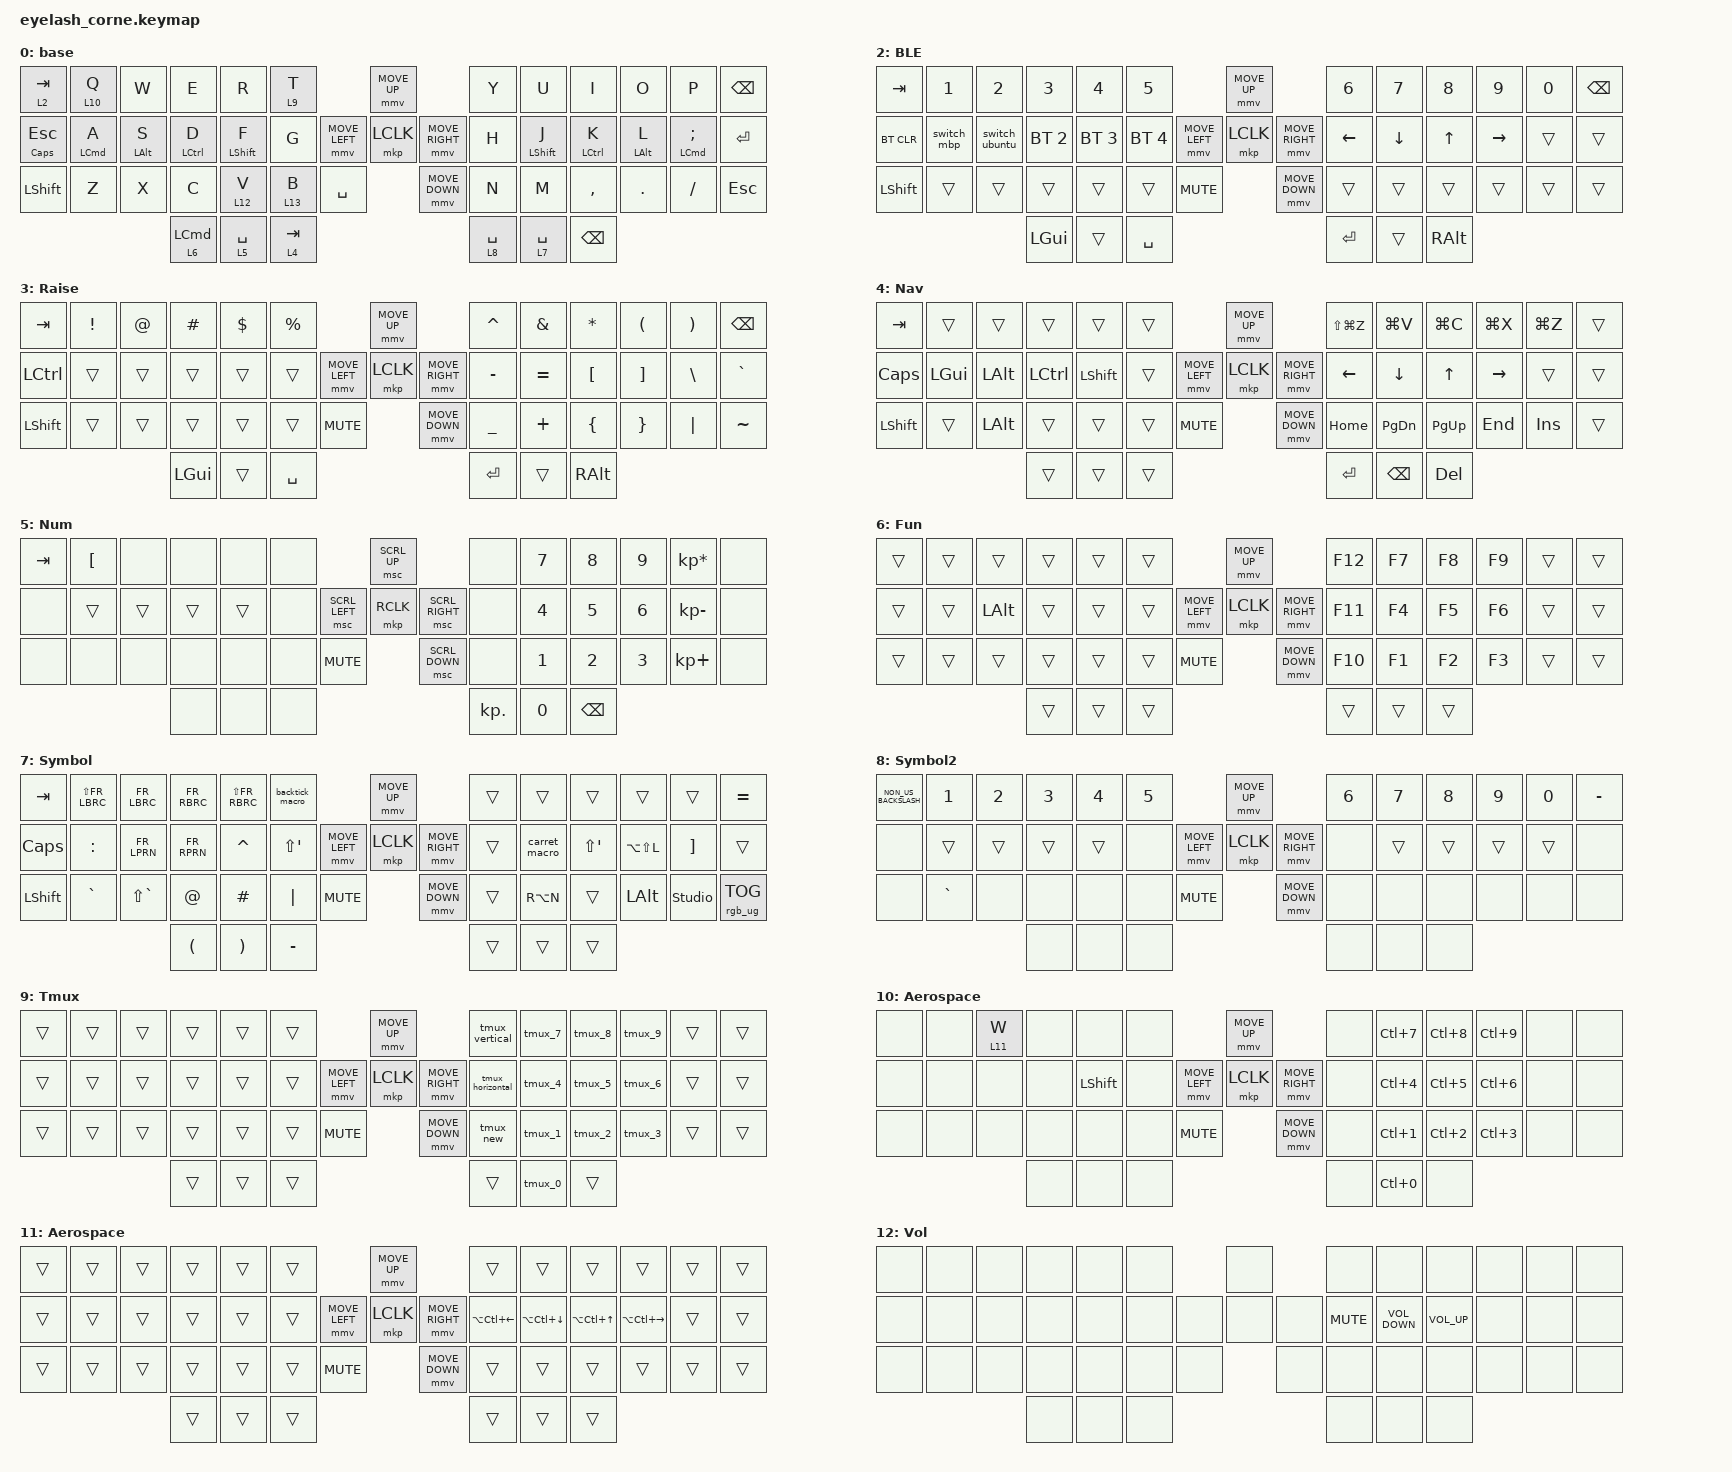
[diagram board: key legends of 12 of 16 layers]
#define ZMK_POINTING_DEFAULT_MOVE_VAL 1200  // 600
#define ZMK_POINTING_DEFAULT_SCRL_VAL 25   // 10

#include "keymap_french.h"
#include <input/processors.dtsi>
#include <zephyr/dt-bindings/input/input-event-codes.h>
#include <behaviors.dtsi>
#include <dt-bindings/zmk/bt.h>
#include <dt-bindings/zmk/keys.h>
#include <dt-bindings/zmk/pointing.h>
#include <dt-bindings/zmk/rgb.h>

&mmv_input_listener { input-processors = <&zip_xy_scaler 2 1>; };

&msc_input_listener { input-processors = <&zip_scroll_scaler 2 1>; };

&msc {
    acceleration-exponent = <1>;      // 0
    time-to-max-speed-ms = <100>;       // 300
    delay-ms = <0>;                   // 0
};

&mmv {
    time-to-max-speed-ms = <500>;
    acceleration-exponent = <1>;
    trigger-period-ms = <16>;
};

/ {
    rgb_encoder: rgb_encoder {
        compatible = "zmk,behavior-sensor-rotate";
        #sensor-binding-cells = <0>;
        bindings = <&rgb_ug RGB_BRI>, <&rgb_ug RGB_BRD>;
    };

    scroll_encoder: scroll_encoder {
        compatible = "zmk,behavior-sensor-rotate";
        #sensor-binding-cells = <0>;
        bindings = <&msc SCRL_DOWN>, <&msc SCRL_UP>;

        tap-ms = <100>;
    };

    behaviors {
        u_lt: u_lt {
            compatible = "zmk,behavior-hold-tap";
            label = "U_LT";
            bindings = <&mo>, <&kp>;

            #binding-cells = <2>;
            tapping-term-ms = <150>;
            flavor = "tap-preferred";
            quick-tap-ms = <0>;
            require-prior-idle-ms = <0>;
        };

        u_ht: u_ht {
            compatible = "zmk,behavior-hold-tap";
            label = "U_HT";
            bindings = <&kp>, <&kp>;

            #binding-cells = <2>;
            tapping-term-ms = <150>;
            flavor = "tap-preferred";
            quick-tap-ms = <150>;
        };
    };

    macros {
        carret_macro: carret_macro {
            compatible = "zmk,behavior-macro";
            #binding-cells = <0>;
            bindings = <&kp LBKT &kp SPACE>;
            label = "CARRET_MACRO";
        };

        tmux_0: tmux_0 {
            compatible = "zmk,behavior-macro";
            #binding-cells = <0>;
            bindings = <&kp LC(B) &kp LS(NUMBER_0)>;
            label = "TMUX_0";
        };

        tmux_1: tmux_1 {
            compatible = "zmk,behavior-macro";
            #binding-cells = <0>;
            bindings = <&kp LC(B) &kp LS(NUMBER_1)>;
            label = "TMUX_1";
        };

        tmux_2: tmux_2 {
            compatible = "zmk,behavior-macro";
            #binding-cells = <0>;
            bindings = <&kp LC(B) &kp LS(NUMBER_2)>;
            label = "TMUX_2";
        };

        tmux_3: tmux_3 {
            compatible = "zmk,behavior-macro";
            #binding-cells = <0>;
            bindings = <&kp LC(B) &kp LS(NUMBER_3)>;
            label = "TMUX_3";
        };

        tmux_4: tmux_4 {
            compatible = "zmk,behavior-macro";
            #binding-cells = <0>;
            bindings = <&kp LC(B) &kp LS(NUMBER_4)>;
            label = "TMUX_4";
        };

        tmux_5: tmux_5 {
            compatible = "zmk,behavior-macro";
            #binding-cells = <0>;
            bindings = <&kp LC(B) &kp LS(NUMBER_5)>;
            label = "TMUX_5";
        };

        tmux_6: tmux_6 {
            compatible = "zmk,behavior-macro";
            #binding-cells = <0>;
            bindings = <&kp LC(B) &kp LS(NUMBER_6)>;
            label = "TMUX_6";
        };

        tmux_7: tmux_7 {
            compatible = "zmk,behavior-macro";
            #binding-cells = <0>;
            bindings = <&kp LC(B) &kp LS(NUMBER_7)>;
            label = "TMUX_7";
        };

        tmux_8: tmux_8 {
            compatible = "zmk,behavior-macro";
            #binding-cells = <0>;
            bindings = <&kp LC(B) &kp LS(NUMBER_8)>;
            label = "TMUX_8";
        };

        tmux_9: tmux_9 {
            compatible = "zmk,behavior-macro";
            #binding-cells = <0>;
            bindings = <&kp LC(B) &kp LS(NUMBER_9)>;
            label = "TMUX_9";
        };

        tmux_new: tmux_new {
            compatible = "zmk,behavior-macro";
            #binding-cells = <0>;
            bindings = <&kp LC(B) &kp C>;
            label = "TMUX_NEW";
        };

        tmux_vertical: tmux_vertical {
            compatible = "zmk,behavior-macro";
            #binding-cells = <0>;
            bindings = <&kp LC(B) &kp LS(SINGLE_QUOTE)>;
            label = "TMUX_VERTICAL";
        };

        tmux_horizontal: tmux_horizontal {
            compatible = "zmk,behavior-macro";
            #binding-cells = <0>;
            bindings = <&kp LC(B) &kp NUMBER_3>;
            label = "TMUX_HORIZONTAL";
        };

        switch_ubuntu: switch_ubuntu {
            compatible = "zmk,behavior-macro";
            #binding-cells = <0>;
            bindings = <&bt BT_SEL 1 &to 1>;
            label = "SWITCH_UBUNTU";
        };

        switch_mbp: switch_mbp {
            compatible = "zmk,behavior-macro";
            #binding-cells = <0>;
            bindings = <&bt BT_SEL 0 &to 0>;
            label = "SWITCH_MBP";
        };

        backtick_macro: backtick_macro {
            compatible = "zmk,behavior-macro";
            #binding-cells = <0>;
            bindings = <&kp BACKSLASH &kp SPACE>;
            label = "BACKTICK_MACRO";
        };
    };

    keymap {
        compatible = "zmk,keymap";

        BASE {
            // -----------------------------------------------------------------------------------------
            // |  TAB |  Q  |  W  |  E  |  R  |  T  |   |  Y  |  U   |  I  |  O  |  P  | BKSP |
            // | CTRL |  A  |  S  |  D  |  F  |  G  |   |  H  |  J   |  K  |  L  |  ;  |  '   |
            // | SHFT |  Z  |  X  |  C  |  V  |  B  |   |  N  |  M   |  ,  |  .  |  /  | ESC  |
            //                    | GUI | LWR | SPC |   | ENT | RSE  | ALT |

            display-name = "base";
            bindings = <
&u_lt 2 TAB            &u_lt 10 Q            &kp W             &kp E                 &kp R               &u_lt 9 T                                 &mmv MOVE_UP                     &kp Y          &kp U               &kp I                 &kp O             &kp P                    &kp BSPC
&u_ht CAPSLOCK ESCAPE  &u_ht LEFT_COMMAND A  &u_ht LEFT_ALT S  &u_ht LEFT_CONTROL D  &u_ht LEFT_SHIFT F  &kp G                     &mmv MOVE_LEFT  &mkp LCLK       &mmv MOVE_RIGHT  &kp H          &u_ht LEFT_SHIFT J  &u_ht LEFT_CONTROL K  &u_ht LEFT_ALT L  &u_ht LEFT_COMMAND SEMI  &kp ENTER
&kp LSHFT              &kp Z                 &kp X             &kp C                 &u_lt 12 V          &u_lt 13 B   &kp SPACE                    &mmv MOVE_DOWN                   &kp N          &kp M               &kp COMMA             &kp DOT           &kp FSLH                 &kp ESC
                                                               &u_lt 6 LEFT_COMMAND  &u_lt 5 SPACE       &u_lt 4 TAB                                                                &u_lt 8 SPACE  &u_lt 7 SPACE       &kp BACKSPACE
            >;
        };

        UBUNTU_BASE {
            display-name = "base";
            bindings = <
&u_lt 2 TAB                    &u_lt 10 Q            &kp W              &kp E                 &kp R               &u_lt 9 T                                 &mmv MOVE_UP                     &kp Y         &kp U               &kp I                 &kp O             &kp P                    &kp BSPC
&u_ht LS(LA(LC(LGUI))) ESCAPE  &u_ht LEFT_COMMAND A  &u_ht RIGHT_ALT S  &u_ht LEFT_CONTROL D  &u_ht LEFT_SHIFT F  &kp G                     &mmv MOVE_LEFT  &mkp LCLK       &mmv MOVE_RIGHT  &kp H         &u_ht LEFT_SHIFT J  &u_ht LEFT_CONTROL K  &u_ht LEFT_ALT L  &u_ht LEFT_COMMAND SEMI  &kp ENTER
&kp LSHFT                      &kp Z                 &kp X              &kp C                 &u_lt 12 V          &u_lt 13 B   &kp SPACE                    &mmv MOVE_DOWN                   &kp N         &kp M               &kp COMMA             &kp DOT           &kp FSLH                 &kp ESC
                                                                        &u_lt 6 LEFT_COMMAND  &u_lt 5 SPACE       &u_lt 4 TAB                                                                &u_lt 15 RET  &u_lt 14 SPACE      &kp BACKSPACE
            >;

            label = "UBU_B";
        };

        lower_layer {
            // -----------------------------------------------------------------------------------------
            // |  TAB |  1  |  2  |  3  |  4  |  5  |   |  6  |  7  |  8  |  9  |  0  | BKSP |
            // | BTCLR| BT1 | BT2 | BT3 | BT4 | BT5 |   | LFT | DWN |  UP | RGT |     |      |
            // | SHFT |     |     |     |     |     |   |     |     |     |     |     |      |
            //                    | GUI |     | SPC |   | ENT |     | ALT |

            display-name = "BLE";
            bindings = <
&kp TAB     &kp N1       &kp N2          &kp N3        &kp N4        &kp N5                                      &mmv MOVE_UP                     &kp N6    &kp N7    &kp N8    &kp N9     &kp N0  &kp BSPC
&bt BT_CLR  &switch_mbp  &switch_ubuntu  &bt BT_SEL 2  &bt BT_SEL 3  &bt BT_SEL 4                &mmv MOVE_LEFT  &mkp LCLK       &mmv MOVE_RIGHT  &kp LEFT  &kp DOWN  &kp UP    &kp RIGHT  &trans  &trans
&kp LSHFT   &trans       &trans          &trans        &trans        &trans        &kp C_MUTE                    &mmv MOVE_DOWN                   &trans    &trans    &trans    &trans     &trans  &trans
                                         &kp LGUI      &trans        &kp SPACE                                                                    &kp RET   &trans    &kp RALT
            >;
        };

        raise_layer {
            // -----------------------------------------------------------------------------------------
            // |  TAB |  !  |  @  |  #  |  $  |  %  |   |  ^  |  &  |  *  |  (  |  )  | BKSP |
            // | CTRL |     |     |     |     |     |   |  -  |  =  |  [  |  ]  |  \  |  `   |
            // | SHFT |     |     |     |     |     |   |  _  |  +  |  {  |  }  | "|" |  ~   |
            //                    | GUI |     | SPC |   | ENT |     | ALT |

            display-name = "Raise";
            bindings = <
&kp TAB    &kp EXCL  &kp AT  &kp HASH  &kp DLLR  &kp PRCNT                                &mmv MOVE_UP                     &kp CARET  &kp AMPS   &kp ASTRK  &kp LPAR  &kp RPAR  &kp BSPC
&kp LCTRL  &trans    &trans  &trans    &trans    &trans                   &mmv MOVE_LEFT  &mkp LCLK       &mmv MOVE_RIGHT  &kp MINUS  &kp EQUAL  &kp LBKT   &kp RBKT  &kp BSLH  &kp GRAVE
&kp LSHFT  &trans    &trans  &trans    &trans    &trans     &kp C_MUTE                    &mmv MOVE_DOWN                   &kp UNDER  &kp PLUS   &kp LBRC   &kp RBRC  &kp PIPE  &kp TILDE
                             &kp LGUI  &trans    &kp SPACE                                                                 &kp RET    &trans     &kp RALT
            >;
        };

        NAV {
            display-name = "Nav";
            bindings = <
&kp TAB    &trans    &trans    &trans     &trans     &trans                                &mmv MOVE_UP                     &kp LS(LG(Z))  &kp LG(V)  &kp LG(C)  &kp LG(X)  &kp LG(Z)  &trans
&kp CAPS   &kp LGUI  &kp LALT  &kp LCTRL  &kp LSHFT  &trans                &mmv MOVE_LEFT  &mkp LCLK       &mmv MOVE_RIGHT  &kp LEFT       &kp DOWN   &kp UP     &kp RIGHT  &trans     &trans
&kp LSHFT  &trans    &kp LALT  &trans     &trans     &trans  &kp C_MUTE                    &mmv MOVE_DOWN                   &kp HOME       &kp PG_DN  &kp PG_UP  &kp END    &kp INS    &trans
                               &trans     &trans     &trans                                                                 &kp RET        &kp BSPC   &kp DEL
            >;
        };

        NUM {
            display-name = "Num";
            bindings = <
&kp TAB  &kp LBKT  &none   &none   &none   &none                                &msc SCRL_UP                     &none       &kp N7  &kp N8         &kp N9  &kp KP_ASTERISK  &none
&none    &trans    &trans  &trans  &trans  &none                &msc SCRL_LEFT  &mkp RCLK       &msc SCRL_RIGHT  &none       &kp N4  &kp N5         &kp N6  &kp KP_MINUS     &none
&none    &none     &none   &none   &none   &none  &kp C_MUTE                    &msc SCRL_DOWN                   &none       &kp N1  &kp N2         &kp N3  &kp KP_PLUS      &none
                           &none   &none   &none                                                                 &kp KP_DOT  &kp N0  &kp BACKSPACE
            >;
        };

        FUN {
            display-name = "Fun";
            bindings = <
&trans  &trans  &trans    &trans  &trans  &trans                                &mmv MOVE_UP                     &kp F12  &kp F7  &kp F8  &kp F9  &trans  &trans
&trans  &trans  &kp LALT  &trans  &trans  &trans                &mmv MOVE_LEFT  &mkp LCLK       &mmv MOVE_RIGHT  &kp F11  &kp F4  &kp F5  &kp F6  &trans  &trans
&trans  &trans  &trans    &trans  &trans  &trans  &kp C_MUTE                    &mmv MOVE_DOWN                   &kp F10  &kp F1  &kp F2  &kp F3  &trans  &trans
                          &trans  &trans  &trans                                                                 &trans   &trans  &trans
            >;
        };

        SYM {
            display-name = "Symbol";
            bindings = <
&kp TAB    &kp LS(FR_LBRC)  &kp FR_LBRC    &kp FR_RBRC  &kp LS(FR_RBRC)  &backtick_macro                                     &mmv MOVE_UP                     &trans  &trans         &trans                &trans         &trans             &kp EQUAL
&kp CAPS   &kp COLON        &kp FR_LPRN    &kp FR_RPRN  &kp CARET        &kp LS(SINGLE_QUOTE)                &mmv MOVE_LEFT  &mkp LCLK       &mmv MOVE_RIGHT  &trans  &carret_macro  &kp LS(SINGLE_QUOTE)  &kp LA(LS(L))  &kp RIGHT_BRACKET  &trans
&kp LSHFT  &kp GRAVE        &kp LS(GRAVE)  &kp AT       &kp HASH         &kp PIPE              &kp C_MUTE                    &mmv MOVE_DOWN                   &trans  &kp RA(N)      &trans                &kp LALT       &studio_unlock     &rgb_ug RGB_TOG
                                           &kp LPAR     &kp RPAR         &kp MINUS                                                                            &trans  &trans         &trans
            >;
        };

        SYMBOLS {
            display-name = "Symbol2";
            bindings = <
&kp NON_US_BACKSLASH  &kp N1     &kp N2  &kp N3  &kp N4  &kp N5                                &mmv MOVE_UP                     &kp N6  &kp N7  &kp N8  &kp N9  &kp N0  &kp MINUS
&none                 &trans     &trans  &trans  &trans  &none                 &mmv MOVE_LEFT  &mkp LCLK       &mmv MOVE_RIGHT  &none   &trans  &trans  &trans  &trans  &none
&none                 &kp GRAVE  &none   &none   &none   &none   &kp C_MUTE                    &mmv MOVE_DOWN                   &none   &none   &none   &none   &none   &none
                                         &none   &none   &none                                                                  &none   &none   &none
            >;
        };

        tmux {
            display-name = "Tmux";
            bindings = <
&trans  &trans  &trans  &trans  &trans  &trans                                &mmv MOVE_UP                     &tmux_vertical    &tmux_7  &tmux_8  &tmux_9  &trans  &trans
&trans  &trans  &trans  &trans  &trans  &trans                &mmv MOVE_LEFT  &mkp LCLK       &mmv MOVE_RIGHT  &tmux_horizontal  &tmux_4  &tmux_5  &tmux_6  &trans  &trans
&trans  &trans  &trans  &trans  &trans  &trans  &kp C_MUTE                    &mmv MOVE_DOWN                   &tmux_new         &tmux_1  &tmux_2  &tmux_3  &trans  &trans
                        &trans  &trans  &trans                                                                 &trans            &tmux_0  &trans
            >;
        };

        aerospace {
            display-name = "Aerospace";
            bindings = <
&none  &none  &lt 11 W  &none  &none           &none                                &mmv MOVE_UP                     &none  &kp LC(NUMBER_7)  &kp LC(NUMBER_8)  &kp LC(NUMBER_9)  &none  &none
&none  &none  &none     &none  &kp LEFT_SHIFT  &none                &mmv MOVE_LEFT  &mkp LCLK       &mmv MOVE_RIGHT  &none  &kp LC(NUMBER_4)  &kp LC(NUMBER_5)  &kp LC(NUMBER_6)  &none  &none
&none  &none  &none     &none  &none           &none  &kp C_MUTE                    &mmv MOVE_DOWN                   &none  &kp LC(NUMBER_1)  &kp LC(NUMBER_2)  &kp LC(NUMBER_3)  &none  &none
                        &none  &none           &none                                                                 &none  &kp LC(NUMBER_0)  &none
            >;
        };

        aerospace_move {
            display-name = "Aerospace";
            bindings = <
&trans  &trans  &trans  &trans  &trans  &trans                                &mmv MOVE_UP                     &trans            &trans            &trans                &trans             &trans  &trans
&trans  &trans  &trans  &trans  &trans  &trans                &mmv MOVE_LEFT  &mkp LCLK       &mmv MOVE_RIGHT  &kp LA(LC(LEFT))  &kp LA(LC(DOWN))  &kp LA(LC(UP_ARROW))  &kp LA(LC(RIGHT))  &trans  &trans
&trans  &trans  &trans  &trans  &trans  &trans  &kp C_MUTE                    &mmv MOVE_DOWN                   &trans            &trans            &trans                &trans             &trans  &trans
                        &trans  &trans  &trans                                                                 &trans            &trans            &trans
            >;
        };

        Volume {
            bindings = <
&none  &none  &none  &none  &none  &none                  &none         &none       &none              &none            &none  &none  &none
&none  &none  &none  &none  &none  &none           &none  &none  &none  &kp K_MUTE  &kp C_VOLUME_DOWN  &kp C_VOLUME_UP  &none  &none  &none
&none  &none  &none  &none  &none  &none  &none           &none         &none       &none              &none            &none  &none  &none
                     &none  &none  &none                                &none       &none              &none
            >;

            label = "Vol";
        };

        Brightness {
            bindings = <
&none  &none  &none  &none  &none  &none                  &none         &none  &none                 &none                 &none  &none  &none
&none  &none  &none  &none  &none  &none           &none  &none  &none  &none  &kp C_BRIGHTNESS_DEC  &kp C_BRIGHTNESS_INC  &none  &none  &none
&none  &none  &none  &none  &none  &none  &none           &none         &none  &none                 &none                 &none  &none  &none
                     &none  &none  &none                                &none  &none                 &none
            >;

            label = "Bright";
        };

        UBUNTU_SYM {
            display-name = "UBU_SYM";
            bindings = <
&kp RA(N3)  &kp RA(LEFT_BRACKET)  &kp RA(N9)                &kp RA(N0)   &kp RA(RIGHT_BRACKET)  &kp LA(BACKSLASH)                                &mmv MOVE_UP                     &trans  &trans         &trans                &trans         &trans             &kp EQUAL
&trans      &kp COLON             &kp FR_LPRN               &kp FR_RPRN  &kp CARET              &kp GRAVE                        &mmv MOVE_LEFT  &mkp LCLK       &mmv MOVE_RIGHT  &trans  &carret_macro  &kp LS(SINGLE_QUOTE)  &kp LS(RA(L))  &kp RIGHT_BRACKET  &trans
&trans      &kp NON_US_BACKSLASH  &kp LS(NON_US_BACKSLASH)  &kp AT       &kp HASH               &kp PIPE           &kp C_MUTE                    &mmv MOVE_DOWN                   &trans  &kp RA(SLASH)  &trans                &kp LALT       &studio_unlock     &rgb_ug RGB_TOG
                                                            &kp LPAR     &kp RPAR               &kp MINUS                                                                         &trans  &trans         &trans
            >;
        };

        UBUNTU_SYMBOLS {
            display-name = "Symbol2";
            bindings = <
&kp RA(NUMBER_2)  &kp N1     &kp N2  &kp N3  &kp N4  &kp N5                                &mmv MOVE_UP                     &kp N6  &kp N7  &kp N8  &kp N9  &kp N0  &kp MINUS
&none             &trans     &trans  &trans  &mo 14  &none                 &mmv MOVE_LEFT  &mkp LCLK       &mmv MOVE_RIGHT  &none   &trans  &trans  &trans  &trans  &none
&none             &kp GRAVE  &none   &none   &none   &none   &kp C_MUTE                    &mmv MOVE_DOWN                   &none   &none   &none   &none   &none   &none
                                     &none   &none   &none                                                                  &none   &none   &none
            >;

            label = "UBU_SYM2";
        };
    };
};
